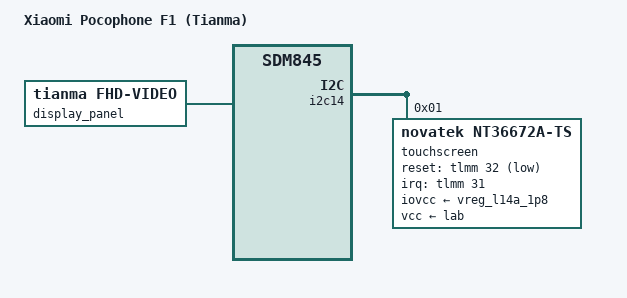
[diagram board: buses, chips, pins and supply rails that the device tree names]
// SPDX-License-Identifier: GPL-2.0

/dts-v1/;

#include "sdm845-xiaomi-beryllium-common.dtsi"

/ {
	model = "Xiaomi Pocophone F1 (Tianma)";
	compatible = "xiaomi,beryllium", "qcom,sdm845";
};

&display_panel {
	compatible = "tianma,fhd-video", "novatek,nt36672a";
	status = "okay";
};

&i2c14 {
	status = "okay";

	touchscreen@1 {
		compatible = "novatek,nt36672a-ts";
		reg = <0x01>;

		interrupts-extended = <&tlmm 31 IRQ_TYPE_EDGE_RISING>;
		reset-gpios = <&tlmm 32 GPIO_ACTIVE_LOW>;
		panel = <&display_panel>;

		iovcc-supply = <&vreg_l14a_1p8>;
		vcc-supply = <&lab>;

		pinctrl-0 = <&ts_int_default &ts_reset_default>;
		pinctrl-1 = <&ts_int_sleep &ts_reset_sleep>;
		pinctrl-names = "default", "sleep";

		touchscreen-size-x = <1080>;
		touchscreen-size-y = <2246>;
	};
};
